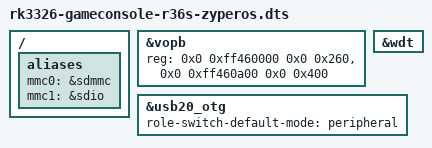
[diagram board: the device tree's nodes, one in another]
// SPDX-License-Identifier: (GPL-2.0+ OR MIT)
/*
 * ZyperOS's R36S device tree: ROCKNIX's (rk3326-gameconsole-r36s.dts,
 * unchanged beside it) with the card the R36S boots from first among the
 * SD cards, and the display's gamma table (below). The RK3326's boot ROM starts from the sdmmc controller alone,
 * so the card that holds this system is always there; ROCKNIX's tree names
 * the sdio controller mmc0, which made the boot card mmcblk1. plastron's
 * scripts, the boot script's root= and ZyperOS find the system's card as
 * mmcblk0, as on the Pixel 2, so the two are swapped here. The other slot,
 * on sdio, is mmcblk1. (docs/devices/r36s.md, "The card")
 */
#include "rk3326-gameconsole-r36s.dts"

/ {
	aliases {
		mmc0 = &sdmmc;
		mmc1 = &sdio;
	};
};

/*
 * The VOP's gamma LUT as its second range, as on the Pixel 2
 * (rk3326s-gkd-pixel2.dts, kernel patch 7): without it the driver gives the
 * display no GAMMA_LUT, and ZyperOS's Screen Colors, Night Mode, the two
 * dimmest brightness rungs and the brightness boost past the top, all made
 * by that table, did nothing on the first R36S that ran ZyperOS (Sylver,
 * 2026-11-23: "the 3 additional high levels are not changing brightness").
 */
&vopb {
	reg = <0x0 0xff460000 0x0 0x260>, <0x0 0xff460a00 0x0 0x400>;
	reg-names = "regs", "gamma_lut";
};

/*
 * The PX30's watchdog, px30.dtsi's, disabled there and in ROCKNIX's tree: on,
 * as on the Pixel 2 (rk3326s-gkd-pixel2.dts). The R36S boots the Pixel 2's
 * U-Boot, which starts it (board/px2/u-boot/px2.config: 30 s asked, one TOP
 * of 2^31 cycles at its 100 MHz clock, 21.5 s, its reset at the first), and
 * with this off nothing in Linux petted it: the chip reset itself about 21 s
 * into every start, the RK817 left on, so the card stayed in its 1.8 V
 * signalling and the boot ROM could not read it. The screen black until a
 * power-off, at a quarter of the first start's copy and 5 s into the
 * launcher's tutorial (Tarik's R36S-V21 2024-12-18 2604, 2026-11-28). The
 * kernel pets it from the probe on, plastron's hwdog from init's first step
 * (r36s_defconfig, boot-prelude.cmd's watchdog.open_timeout).
 */
&wdt {
	status = "okay";
};

/*
 * The OTG port a device from the controller's probe, not a host until
 * S40usbgadget and usbrole make it one (rk3326.dtsi's default, the Pixel
 * 2's, is host). As a host the controller turns on its vbus-supply, the
 * RK817's otg_switch, and the port puts 5 V out: test.3's first start read
 * 5.0 V on the RK817's VUSB with nothing plugged in, its log written as the
 * role went to device 66 s in, after the first start's copy (Tarik's
 * R36S-V21, 2026-11-28). A computer on the cable then is fed by the R36S for
 * as long as the start takes. A device never feeds anything.
 */
&usb20_otg {
	role-switch-default-mode = "peripheral";
};
